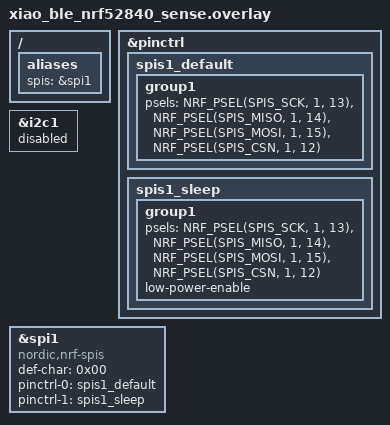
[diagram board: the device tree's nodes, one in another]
/*
 * Copyright (c) 2026 Jjateen Gundesha <jjateen97@gmail.com>
 * SPDX-License-Identifier: Apache-2.0
 *
 * XIAO nRF52840 Sense pin mapping (XIAO connector):
 *   D8 / P1.13 -> SPIS SCK
 *   D9 / P1.14 -> SPIS MISO
 *  D10 / P1.15 -> SPIS MOSI
 *   D7 / P1.12 -> SPIS CSN
 *
 * spi1 (0x40004000) is used as SPIS; it shares the peripheral address with
 * i2c1 so both cannot be enabled simultaneously.
 */

&pinctrl {
	spis1_default: spis1_default {
		group1 {
			psels = <NRF_PSEL(SPIS_SCK,  1, 13)>,
				<NRF_PSEL(SPIS_MISO, 1, 14)>,
				<NRF_PSEL(SPIS_MOSI, 1, 15)>,
				<NRF_PSEL(SPIS_CSN,  1, 12)>;
		};
	};

	spis1_sleep: spis1_sleep {
		group1 {
			psels = <NRF_PSEL(SPIS_SCK,  1, 13)>,
				<NRF_PSEL(SPIS_MISO, 1, 14)>,
				<NRF_PSEL(SPIS_MOSI, 1, 15)>,
				<NRF_PSEL(SPIS_CSN,  1, 12)>;
			low-power-enable;
		};
	};
};

/* Disable i2c1 since it shares the peripheral with spi1 */
&i2c1 {
	status = "disabled";
};

&spi1 {
	compatible = "nordic,nrf-spis";
	status = "okay";
	def-char = <0x00>;
	pinctrl-0 = <&spis1_default>;
	pinctrl-1 = <&spis1_sleep>;
	pinctrl-names = "default", "sleep";
};

/ {
	aliases {
		spis = &spi1;
	};
};
